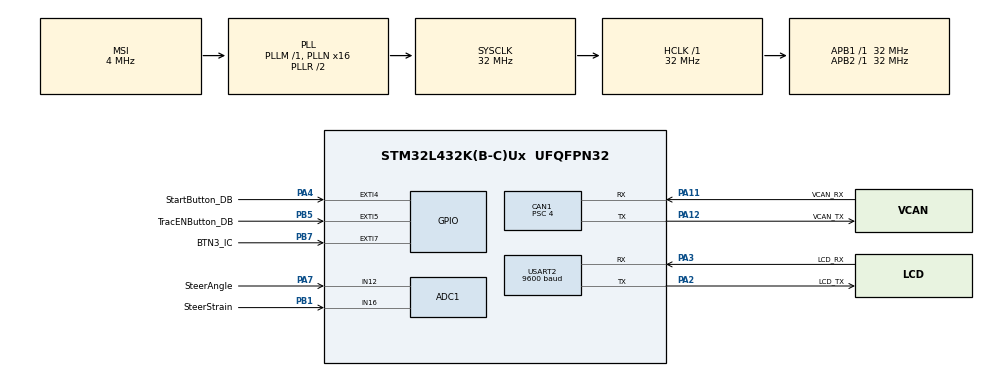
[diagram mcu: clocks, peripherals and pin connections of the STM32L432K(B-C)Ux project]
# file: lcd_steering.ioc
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ADC1.Channel-3\#ChannelRegularConversion=ADC_CHANNEL_12
ADC1.Channel-4\#ChannelRegularConversion=ADC_CHANNEL_16
ADC1.ClockPrescaler=ADC_CLOCK_ASYNC_DIV4
ADC1.ContinuousConvMode=ENABLE
ADC1.NbrOfConversion=2
ADC1.NbrOfConversionFlag=1
ADC1.OffsetNumber-3\#ChannelRegularConversion=ADC_OFFSET_NONE
ADC1.OffsetNumber-4\#ChannelRegularConversion=ADC_OFFSET_NONE
ADC1.Rank-3\#ChannelRegularConversion=1
ADC1.Rank-4\#ChannelRegularConversion=2
ADC1.SamplingTime-3\#ChannelRegularConversion=ADC_SAMPLETIME_247CYCLES_5
ADC1.SamplingTime-4\#ChannelRegularConversion=ADC_SAMPLETIME_247CYCLES_5
ADC1.master=1
CAN1.ABOM=ENABLE
CAN1.AWUM=DISABLE
CAN1.BS1=CAN_BS1_9TQ
CAN1.BS2=CAN_BS2_6TQ
CAN1.CalculateTimeQuantum=125.0
CAN1.Prescaler=4
FREERTOS.INCLUDE_vTaskDelayUntil=1
FREERTOS.Tasks01=defaultTask,0,256,StartDefaultTask,Default,NULL,Dynamic,NULL,NULL
FREERTOS.configTOTAL_HEAP_SIZE=12000
Mcu.Family=STM32L4
Mcu.Name=STM32L432K(B-C)Ux
Mcu.Package=UFQFPN32
NVIC.CAN1_RX0_IRQn=true\:5\:0\:true\:false\:true\:true\:true\:true
NVIC.CAN1_RX1_IRQn=true\:5\:0\:true\:false\:true\:true\:true\:true
NVIC.CAN1_TX_IRQn=true\:5\:0\:true\:false\:true\:true\:true\:true
NVIC.EXTI4_IRQn=true\:0\:0\:false\:false\:true\:true\:true\:true
NVIC.EXTI9_5_IRQn=true\:0\:0\:false\:false\:true\:true\:true\:true
NVIC.PriorityGroup=NVIC_PRIORITYGROUP_4
NVIC.TIM1_UP_TIM16_IRQn=true\:0\:0\:false\:false\:true\:false\:false\:true
NVIC.TimeBase=TIM1_UP_TIM16_IRQn
NVIC.TimeBaseIP=TIM1
NVIC.USART2_IRQn=true\:0\:0\:false\:false\:true\:true\:true\:true
PA0.Signal=RCC_CK_IN
PA11.GPIO_Label=VCAN_RX
PA11.Mode=Master
PA11.Signal=CAN1_RX
PA12.GPIO_Label=VCAN_TX
PA12.Mode=Master
PA12.Signal=CAN1_TX
PA13\ (JTMS-SWDIO).Mode=Serial_Wire
PA13\ (JTMS-SWDIO).Signal=SYS_JTMS-SWDIO
PA14\ (JTCK-SWCLK).Mode=Serial_Wire
PA14\ (JTCK-SWCLK).Signal=SYS_JTCK-SWCLK
PA2.GPIO_Label=LCD_TX
PA2.Mode=Asynchronous
PA2.Signal=USART2_TX
PA3.GPIO_Label=LCD_RX
PA3.Mode=Asynchronous
PA3.Signal=USART2_RX
PA4.GPIO_Label=StartButton_DB
PA4.Signal=GPXTI4
PA7.GPIO_Label=SteerAngle
PA7.Signal=ADCx_IN12
PB0.GPIO_Label=Strain_Ref
PB0.Signal=ADCx_IN15
PB1.GPIO_Label=SteerStrain
PB1.Signal=ADCx_IN16
PB5.GPIO_Label=TracENButton_DB
PB5.Signal=GPXTI5
PB7.GPIO_Label=BTN3_IC
PB7.Signal=GPXTI7
PC14-OSC32_IN\ (PC14).Signal=RCC_OSC32_IN
PC15-OSC32_OUT\ (PC15).Signal=RCC_OSC32_OUT
ProjectManager.HeapSize=0x200
ProjectManager.StackSize=0x400
ProjectManager.TargetToolchain=SW4STM32
RCC.ADCFreq_Value=32000000
RCC.AHBFreq_Value=32000000
RCC.APB1Freq_Value=32000000
RCC.APB1TimFreq_Value=32000000
RCC.APB2Freq_Value=32000000
RCC.APB2TimFreq_Value=32000000
RCC.CortexFreq_Value=32000000
RCC.HCLKFreq_Value=32000000
RCC.HSE_VALUE=8000000
RCC.HSI48_VALUE=48000000
RCC.HSI_VALUE=16000000
RCC.LSE_VALUE=32768
RCC.MSI_VALUE=4000000
RCC.PLLN=16
RCC.PLLSAI1N=16
RCC.SYSCLKFreq_VALUE=32000000
RCC.SYSCLKSource=RCC_SYSCLKSOURCE_PLLCLK
RCC.USBFreq_Value=32000000
RCC.VCOOutputFreq_Value=64000000
SH.ADCx_IN12.0=ADC1_IN12,IN12-Single-Ended
SH.ADCx_IN15.0=ADC1_IN15
SH.ADCx_IN16.0=ADC1_IN16,IN16-Single-Ended
USART2.BaudRate=9600
USART2.SwapParam=ADVFEATURE_SWAP_ENABLE
USART2.VirtualMode-Asynchronous=VM_ASYNC
VP_FREERTOS_VS_CMSIS_V1.Mode=CMSIS_V1
VP_SYS_VS_tim1.Mode=TIM1
board=custom

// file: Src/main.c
/* USER CODE BEGIN Header */
/**
  ******************************************************************************
  * @file           : main.c
  * @brief          : Main program body
  ******************************************************************************
  * @attention
  *
  * <h2><center>&copy; Copyright (c) 2020 STMicroelectronics.
  * All rights reserved.</center></h2>
  *
  * This software component is licensed by ST under Ultimate Liberty license
  * SLA0044, the "License"; You may not use this file except in compliance with
  * the License. You may obtain a copy of the License at:
  *                             www.st.com/SLA0044
  *
  ******************************************************************************
  */
/* USER CODE END Header */
#include "main.h"
#include "cmsis_os.h"

/* USER CODE BEGIN Includes */
#include "can_usr.h"
#include "stm32l4xx_hal_uart.h"
/* USER CODE END Includes */

ADC_HandleTypeDef hadc1;

CAN_HandleTypeDef hcan1;

UART_HandleTypeDef huart2;

osThreadId defaultTaskHandle;
/* USER CODE BEGIN PV */
/* Private variables ---------------------------------------------------------*/
uint8_t myrx_data[RX_SIZE_UART];
/* USER CODE END PV */

void SystemClock_Config(void);
static void MX_GPIO_Init(void);
static void MX_CAN1_Init(void);
static void MX_ADC1_Init(void);
static void MX_USART2_UART_Init(void);
void StartDefaultTask(void const * argument);

/* USER CODE BEGIN PFP */
/* Private function prototypes -----------------------------------------------*/

/* USER CODE END PFP */

int main(void)
{

  /* MCU Configuration--------------------------------------------------------*/

  /* Reset of all peripherals, Initializes the Flash interface and the Systick. */
  HAL_Init();

  /* Configure the system clock */
  SystemClock_Config();

  /* USER CODE BEGIN SysInit */
  HAL_Delay(DELAY_STARTUP);

  /* USER CODE END SysInit */

  /* Initialize all configured peripherals */
  MX_GPIO_Init();
  MX_CAN1_Init();
  MX_ADC1_Init();
  MX_USART2_UART_Init();
  /* USER CODE BEGIN 2 */

  HAL_Delay(DELAY_UART);
  initRTOSObjects(); //start tasks

  can_filter_init(&hcan1);
  HAL_Delay(DELAY_UART);
  HAL_CAN_Start(&hcan1);
  //__HAL_UART_ENABLE_IT(&huart1, UART_IT_TC);
//  __HAL_UART_ENABLE_IT(&huart1, UART_IT_RXNE);

  HAL_CAN_ActivateNotification(&hcan1, CAN_IT_RX_FIFO0_MSG_PENDING);
  HAL_CAN_ActivateNotification(&hcan1, CAN_IT_RX_FIFO1_MSG_PENDING);

  /* USER CODE END 2 */

  /* Create the thread(s) */
  /* definition and creation of defaultTask */
  osThreadDef(defaultTask, StartDefaultTask, osPriorityNormal, 0, 256);
  defaultTaskHandle = osThreadCreate(osThread(defaultTask), NULL);

  /* Start scheduler */
  osKernelStart();

  /* We should never get here as control is now taken by the scheduler */
  /* Infinite loop */
  while (1)
  {

  }
}

void SystemClock_Config(void)
{
  RCC_OscInitTypeDef RCC_OscInitStruct = {0};
  RCC_ClkInitTypeDef RCC_ClkInitStruct = {0};
  RCC_PeriphCLKInitTypeDef PeriphClkInit = {0};

  /** Initializes the RCC Oscillators according to the specified parameters
  * in the RCC_OscInitTypeDef structure.
  */
  RCC_OscInitStruct.OscillatorType = RCC_OSCILLATORTYPE_MSI;
  RCC_OscInitStruct.MSIState = RCC_MSI_ON;
  RCC_OscInitStruct.MSICalibrationValue = 0;
  RCC_OscInitStruct.MSIClockRange = RCC_MSIRANGE_6;
  RCC_OscInitStruct.PLL.PLLState = RCC_PLL_ON;
  RCC_OscInitStruct.PLL.PLLSource = RCC_PLLSOURCE_MSI;
  RCC_OscInitStruct.PLL.PLLM = 1;
  RCC_OscInitStruct.PLL.PLLN = 16;
  RCC_OscInitStruct.PLL.PLLP = RCC_PLLP_DIV7;
  RCC_OscInitStruct.PLL.PLLQ = RCC_PLLQ_DIV2;
  RCC_OscInitStruct.PLL.PLLR = RCC_PLLR_DIV2;
  if (HAL_RCC_OscConfig(&RCC_OscInitStruct) != HAL_OK)
  {
    Error_Handler();
  }
  /** Initializes the CPU, AHB and APB buses clocks
  */
  RCC_ClkInitStruct.ClockType = RCC_CLOCKTYPE_HCLK|RCC_CLOCKTYPE_SYSCLK
                              |RCC_CLOCKTYPE_PCLK1|RCC_CLOCKTYPE_PCLK2;
  RCC_ClkInitStruct.SYSCLKSource = RCC_SYSCLKSOURCE_PLLCLK;
  RCC_ClkInitStruct.AHBCLKDivider = RCC_SYSCLK_DIV1;
  RCC_ClkInitStruct.APB1CLKDivider = RCC_HCLK_DIV1;
  RCC_ClkInitStruct.APB2CLKDivider = RCC_HCLK_DIV1;

  if (HAL_RCC_ClockConfig(&RCC_ClkInitStruct, FLASH_LATENCY_1) != HAL_OK)
  {
    Error_Handler();
  }
  PeriphClkInit.PeriphClockSelection = RCC_PERIPHCLK_USART2|RCC_PERIPHCLK_ADC;
  PeriphClkInit.Usart2ClockSelection = RCC_USART2CLKSOURCE_PCLK1;
  PeriphClkInit.AdcClockSelection = RCC_ADCCLKSOURCE_PLLSAI1;
  PeriphClkInit.PLLSAI1.PLLSAI1Source = RCC_PLLSOURCE_MSI;
  PeriphClkInit.PLLSAI1.PLLSAI1M = 1;
  PeriphClkInit.PLLSAI1.PLLSAI1N = 16;
  PeriphClkInit.PLLSAI1.PLLSAI1P = RCC_PLLP_DIV7;
  PeriphClkInit.PLLSAI1.PLLSAI1Q = RCC_PLLQ_DIV2;
  PeriphClkInit.PLLSAI1.PLLSAI1R = RCC_PLLR_DIV2;
  PeriphClkInit.PLLSAI1.PLLSAI1ClockOut = RCC_PLLSAI1_ADC1CLK;
  if (HAL_RCCEx_PeriphCLKConfig(&PeriphClkInit) != HAL_OK)
  {
    Error_Handler();
  }
  /** Configure the main internal regulator output voltage
  */
  if (HAL_PWREx_ControlVoltageScaling(PWR_REGULATOR_VOLTAGE_SCALE1) != HAL_OK)
  {
    Error_Handler();
  }
}

static void MX_ADC1_Init(void)
{

  ADC_ChannelConfTypeDef sConfig = {0};

  /** Common config
  */
  hadc1.Instance = ADC1;
  hadc1.Init.ClockPrescaler = ADC_CLOCK_ASYNC_DIV4;
  hadc1.Init.Resolution = ADC_RESOLUTION_12B;
  hadc1.Init.DataAlign = ADC_DATAALIGN_RIGHT;
  hadc1.Init.ScanConvMode = ADC_SCAN_ENABLE;
  hadc1.Init.EOCSelection = ADC_EOC_SINGLE_CONV;
  hadc1.Init.LowPowerAutoWait = DISABLE;
  hadc1.Init.ContinuousConvMode = ENABLE;
  hadc1.Init.NbrOfConversion = 2;
  hadc1.Init.DiscontinuousConvMode = DISABLE;
  hadc1.Init.ExternalTrigConv = ADC_SOFTWARE_START;
  hadc1.Init.ExternalTrigConvEdge = ADC_EXTERNALTRIGCONVEDGE_NONE;
  hadc1.Init.DMAContinuousRequests = DISABLE;
  hadc1.Init.Overrun = ADC_OVR_DATA_PRESERVED;
  hadc1.Init.OversamplingMode = DISABLE;
  if (HAL_ADC_Init(&hadc1) != HAL_OK)
  {
    Error_Handler();
  }
  /** Configure Regular Channel
  */
  sConfig.Channel = ADC_CHANNEL_12;
  sConfig.Rank = ADC_REGULAR_RANK_1;
  sConfig.SamplingTime = ADC_SAMPLETIME_247CYCLES_5;
  sConfig.SingleDiff = ADC_SINGLE_ENDED;
  sConfig.OffsetNumber = ADC_OFFSET_NONE;
  sConfig.Offset = 0;
  if (HAL_ADC_ConfigChannel(&hadc1, &sConfig) != HAL_OK)
  {
    Error_Handler();
  }
  /** Configure Regular Channel
  */
  sConfig.Channel = ADC_CHANNEL_16;
  sConfig.Rank = ADC_REGULAR_RANK_2;
  if (HAL_ADC_ConfigChannel(&hadc1, &sConfig) != HAL_OK)
  {
    Error_Handler();
  }

}

static void MX_CAN1_Init(void)
{

  hcan1.Instance = CAN1;
  hcan1.Init.Prescaler = 4;
  hcan1.Init.Mode = CAN_MODE_NORMAL;
  hcan1.Init.SyncJumpWidth = CAN_SJW_1TQ;
  hcan1.Init.TimeSeg1 = CAN_BS1_9TQ;
  hcan1.Init.TimeSeg2 = CAN_BS2_6TQ;
  hcan1.Init.TimeTriggeredMode = DISABLE;
  hcan1.Init.AutoBusOff = ENABLE;
  hcan1.Init.AutoWakeUp = DISABLE;
  hcan1.Init.AutoRetransmission = DISABLE;
  hcan1.Init.ReceiveFifoLocked = DISABLE;
  hcan1.Init.TransmitFifoPriority = DISABLE;
  if (HAL_CAN_Init(&hcan1) != HAL_OK)
  {
    Error_Handler();
  }

}

static void MX_USART2_UART_Init(void)
{

  huart2.Instance = USART2;
  huart2.Init.BaudRate = 9600;
  huart2.Init.WordLength = UART_WORDLENGTH_8B;
  huart2.Init.StopBits = UART_STOPBITS_1;
  huart2.Init.Parity = UART_PARITY_NONE;
  huart2.Init.Mode = UART_MODE_TX_RX;
  huart2.Init.HwFlowCtl = UART_HWCONTROL_NONE;
  huart2.Init.OverSampling = UART_OVERSAMPLING_16;
  huart2.Init.OneBitSampling = UART_ONE_BIT_SAMPLE_DISABLE;
  huart2.AdvancedInit.AdvFeatureInit = UART_ADVFEATURE_SWAP_INIT;
  huart2.AdvancedInit.Swap = UART_ADVFEATURE_SWAP_ENABLE;
  if (HAL_UART_Init(&huart2) != HAL_OK)
  {
    Error_Handler();
  }

}

static void MX_GPIO_Init(void)
{
  GPIO_InitTypeDef GPIO_InitStruct = {0};

  /* GPIO Ports Clock Enable */
  __HAL_RCC_GPIOC_CLK_ENABLE();
  __HAL_RCC_GPIOA_CLK_ENABLE();
  __HAL_RCC_GPIOB_CLK_ENABLE();

  /*Configure GPIO pin : StartButton_DB_Pin */
  GPIO_InitStruct.Pin = StartButton_DB_Pin;
  GPIO_InitStruct.Mode = GPIO_MODE_IT_RISING;
  GPIO_InitStruct.Pull = GPIO_NOPULL;
  HAL_GPIO_Init(StartButton_DB_GPIO_Port, &GPIO_InitStruct);

  /*Configure GPIO pins : TracENButton_DB_Pin BTN3_IC_Pin */
  GPIO_InitStruct.Pin = TracENButton_DB_Pin|BTN3_IC_Pin;
  GPIO_InitStruct.Mode = GPIO_MODE_IT_RISING;
  GPIO_InitStruct.Pull = GPIO_NOPULL;
  HAL_GPIO_Init(GPIOB, &GPIO_InitStruct);

  /* EXTI interrupt init*/
  HAL_NVIC_SetPriority(EXTI4_IRQn, 15, 15);
  HAL_NVIC_EnableIRQ(EXTI4_IRQn);

  HAL_NVIC_SetPriority(EXTI9_5_IRQn, 0, 0);
  HAL_NVIC_EnableIRQ(EXTI9_5_IRQn);

}

void StartDefaultTask(void const * argument)
{
  for(;;)
  {
    osDelay(1);
  }
}

void HAL_TIM_PeriodElapsedCallback(TIM_HandleTypeDef *htim)
{
  if (htim->Instance == TIM1) {
    HAL_IncTick();
  }
}

void Error_Handler(void)
{
  while(1)
  {
  }
}

/************************ (C) COPYRIGHT STMicroelectronics *****END OF FILE****/
